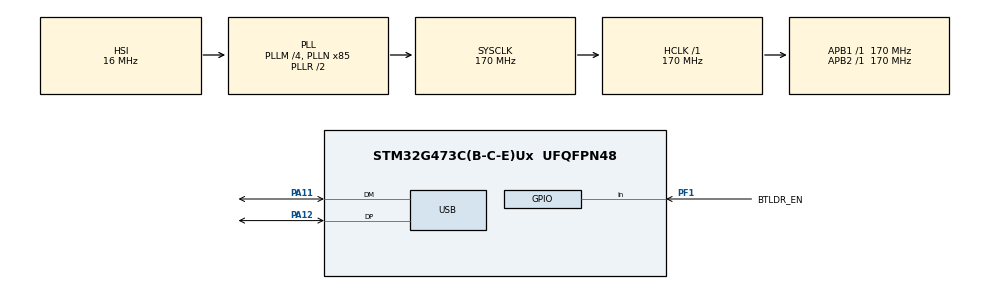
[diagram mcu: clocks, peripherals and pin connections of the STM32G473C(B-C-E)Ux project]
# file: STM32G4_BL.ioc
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Mcu.Family=STM32G4
Mcu.Name=STM32G473C(B-C-E)Ux
Mcu.Package=UFQFPN48
NVIC.PriorityGroup=NVIC_PRIORITYGROUP_4
NVIC.USB_LP_IRQn=true\:0\:0\:false\:false\:true\:true\:true
PA11.Mode=Device
PA11.Signal=USB_DM
PA12.Mode=Device
PA12.Signal=USB_DP
PA13.Mode=Trace_Asynchronous_SW
PA13.Signal=SYS_JTMS-SWDIO
PA14.Mode=Trace_Asynchronous_SW
PA14.Signal=SYS_JTCK-SWCLK
PB3.Mode=Trace_Asynchronous_SW
PB3.Signal=SYS_JTDO-SWO
PF1-OSC_OUT.GPIO_Label=BTLDR_EN
PF1-OSC_OUT.Signal=GPIO_Input
ProjectManager.HeapSize=0x200
ProjectManager.StackSize=0x400
ProjectManager.TargetToolchain=STM32CubeIDE
RCC.ADC12Freq_Value=170000000
RCC.ADC345Freq_Value=170000000
RCC.AHBFreq_Value=170000000
RCC.APB1Freq_Value=170000000
RCC.APB1TimFreq_Value=170000000
RCC.APB2Freq_Value=170000000
RCC.APB2TimFreq_Value=170000000
RCC.CK48CLockSelection=RCC_USBCLKSOURCE_HSI48
RCC.CortexFreq_Value=170000000
RCC.EXTERNAL_CLOCK_VALUE=12288000
RCC.HCLKFreq_Value=170000000
RCC.HSE_VALUE=8000000
RCC.HSI48_VALUE=48000000
RCC.HSI_VALUE=16000000
RCC.LSE_VALUE=32768
RCC.PLLM=RCC_PLLM_DIV4
RCC.PLLN=85
RCC.PLLQ=RCC_PLLQ_DIV6
RCC.SYSCLKFreq_VALUE=170000000
RCC.SYSCLKSource=RCC_SYSCLKSOURCE_PLLCLK
RCC.USBFreq_Value=48000000
RCC.VCOOutputFreq_Value=340000000
USB_DEVICE.CLASS_NAME_FS=MSC
USB_DEVICE.VirtualMode=Msc
USB_DEVICE.VirtualModeFS=Msc_FS
VP_SYS_VS_DBSignals.Mode=DisableDeadBatterySignals
VP_USB_DEVICE_VS_USB_DEVICE_MSC_FS.Mode=MSC_FS
board=custom

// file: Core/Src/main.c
/* USER CODE BEGIN Header */
/**
  ******************************************************************************
  * @file           : main.c
  * @brief          : Main program body
  ******************************************************************************
  * @attention
  *
  * <h2><center>&copy; Copyright (c) 2021 STMicroelectronics.
  * All rights reserved.</center></h2>
  *
  * This software component is licensed by ST under BSD 3-Clause license,
  * the "License"; You may not use this file except in compliance with the
  * License. You may obtain a copy of the License at:
  *                        opensource.org/licenses/BSD-3-Clause
  *
  * This bootloader project ported from https://github.com/sfyip/STM32F103_MSD_BOOTLOADER
  * by Brian Schmalz of SchmalzHaus LLC, August 2021.
  *
  ******************************************************************************
  */
/* USER CODE END Header */
#include "main.h"
#include "usb_device.h"
#include "gpio.h"

/* USER CODE BEGIN Includes */
#include <stdint.h>
#include <stdbool.h>
#include "btldr_config.h"
/* USER CODE END Includes */

void SystemClock_Config(void);

/* USER CODE BEGIN 0 */
bool is_appcode_exist()
{
  uint32_t *mem = (uint32_t*)APP_ADDR;

  if ((mem[0] == 0x00000000 || mem[0] == 0xFFFFFFFF) && \
      (mem[1] == 0x00000000 || mem[1] == 0xFFFFFFFF) && \
      (mem[2] == 0x00000000 || mem[2] == 0xFFFFFFFF) && \
      (mem[3] == 0x00000000 || mem[3] == 0xFFFFFFFF))
  {
    return false;
  }
  else
  {
    return true;
  }
}

void jmp_to_appcode()
{
  /* Function pointer to the address of the user application. */
  uint32_t jump_addr = *((__IO uint32_t*)(APP_ADDR+4u));
  __disable_irq();
  HAL_DeInit();
  /* Change the main stack pointer. */
  __set_MSP(*(__IO uint32_t*)APP_ADDR);
  SCB->VTOR = APP_ADDR;

  ((void (*) (void)) (jump_addr)) ();
}

/* USER CODE END 0 */

int main(void)
{

  /* MCU Configuration--------------------------------------------------------*/

  /* Reset of all peripherals, Initializes the Flash interface and the Systick. */
  HAL_Init();

  /* Configure the system clock */
  SystemClock_Config();

  /* Initialize all configured peripherals */
  MX_GPIO_Init();
  //MX_USB_Device_Init();
  /* USER CODE BEGIN 2 */
  /* The above call to MX_USB_Device_Init(); needs to be commented out. CubeMX will put it back, but we need
   * to conditionally init USB only if we need to actually run the bootloader.
   */
  Debug_SWOInit(0x00000001, 170000000, 2000000);

  /*
   * TODO: Make a 10 minute timeout for waiting for the user to copy a file over. If, after that time, there is no
   * file copied, then jump to the app (if it exists)
   *
   * TODO: Remove is_button_down() as trigger (done)
   *
   * TODO: Add 'double tap on reset button' as trigger (how?)
   *
   * TODO: Add code to erase second bank of flash (test with larger hex file)
   *
   * TODO: Add support for UF2 files (stretch goal)
   *
   * TODO: Add magic number method for APP to trigger bootloader
   *
   * TODO: Figure out how to make SWO work no matter if DEBUG/RELEASE or if debugger is connected or not
   *
   * TODO: Why is bootloader so big? Use ll libraries instead? How to shrink? (orig was 16KB)
   *
   */

  if(!is_appcode_exist() || (BL_FORCE_RAMLOC == BL_FORCE_RUN_MAGIC))
//  if(!is_appcode_exist())
  {
    uint32_t blink_time = HAL_GetTick();

    // Configure the Bootloader LED to be an output
    GPIO_InitTypeDef GPIO_InitStruct = {0};

    __HAL_RCC_GPIOA_CLK_ENABLE();
    HAL_GPIO_WritePin(BOOTLOADER_LED_PORT, BOOTLOADER_LED_PIN, GPIO_PIN_SET);
    GPIO_InitStruct.Pin = BOOTLOADER_LED_PIN;
    GPIO_InitStruct.Mode = GPIO_MODE_OUTPUT_PP;
    GPIO_InitStruct.Pull = GPIO_NOPULL;
    HAL_GPIO_Init(BOOTLOADER_LED_PORT, &GPIO_InitStruct);

    // Clear the BL_FORCE ram location so that we don't do this again
    BL_FORCE_RAMLOC = 0x00000000;

    printf("Entering bootloader\n");

    MX_USB_Device_Init();
    while(1)
    {
      if ((HAL_GetTick() - blink_time) > 1000)
      {
        if (HAL_GPIO_ReadPin(BOOTLOADER_LED_PORT, BOOTLOADER_LED_PIN) == GPIO_PIN_SET)
        {
          HAL_GPIO_WritePin(BOOTLOADER_LED_PORT, BOOTLOADER_LED_PIN, GPIO_PIN_RESET);
        }
        else
        {
          HAL_GPIO_WritePin(BOOTLOADER_LED_PORT, BOOTLOADER_LED_PIN, GPIO_PIN_SET);
        }
        blink_time = HAL_GetTick();
      }
    }
  }
  else
  {
    printf("Jumping to application.\n");
    jmp_to_appcode();
  }

  /* USER CODE END 2 */

  /* Infinite loop */
  while (1)
  {

  }
}

void SystemClock_Config(void)
{
  RCC_OscInitTypeDef RCC_OscInitStruct = {0};
  RCC_ClkInitTypeDef RCC_ClkInitStruct = {0};
  RCC_PeriphCLKInitTypeDef PeriphClkInit = {0};

  /** Configure the main internal regulator output voltage
  */
  HAL_PWREx_ControlVoltageScaling(PWR_REGULATOR_VOLTAGE_SCALE1_BOOST);
  /** Initializes the RCC Oscillators according to the specified parameters
  * in the RCC_OscInitTypeDef structure.
  */
  RCC_OscInitStruct.OscillatorType = RCC_OSCILLATORTYPE_HSI|RCC_OSCILLATORTYPE_HSI48;
  RCC_OscInitStruct.HSIState = RCC_HSI_ON;
  RCC_OscInitStruct.HSICalibrationValue = RCC_HSICALIBRATION_DEFAULT;
  RCC_OscInitStruct.HSI48State = RCC_HSI48_ON;
  RCC_OscInitStruct.PLL.PLLState = RCC_PLL_ON;
  RCC_OscInitStruct.PLL.PLLSource = RCC_PLLSOURCE_HSI;
  RCC_OscInitStruct.PLL.PLLM = RCC_PLLM_DIV4;
  RCC_OscInitStruct.PLL.PLLN = 85;
  RCC_OscInitStruct.PLL.PLLP = RCC_PLLP_DIV2;
  RCC_OscInitStruct.PLL.PLLQ = RCC_PLLQ_DIV6;
  RCC_OscInitStruct.PLL.PLLR = RCC_PLLR_DIV2;
  if (HAL_RCC_OscConfig(&RCC_OscInitStruct) != HAL_OK)
  {
    Error_Handler();
  }
  /** Initializes the CPU, AHB and APB buses clocks
  */
  RCC_ClkInitStruct.ClockType = RCC_CLOCKTYPE_HCLK|RCC_CLOCKTYPE_SYSCLK
                              |RCC_CLOCKTYPE_PCLK1|RCC_CLOCKTYPE_PCLK2;
  RCC_ClkInitStruct.SYSCLKSource = RCC_SYSCLKSOURCE_PLLCLK;
  RCC_ClkInitStruct.AHBCLKDivider = RCC_SYSCLK_DIV1;
  RCC_ClkInitStruct.APB1CLKDivider = RCC_HCLK_DIV1;
  RCC_ClkInitStruct.APB2CLKDivider = RCC_HCLK_DIV1;

  if (HAL_RCC_ClockConfig(&RCC_ClkInitStruct, FLASH_LATENCY_4) != HAL_OK)
  {
    Error_Handler();
  }
  /** Initializes the peripherals clocks
  */
  PeriphClkInit.PeriphClockSelection = RCC_PERIPHCLK_USB;
  PeriphClkInit.UsbClockSelection = RCC_USBCLKSOURCE_HSI48;
  if (HAL_RCCEx_PeriphCLKConfig(&PeriphClkInit) != HAL_OK)
  {
    Error_Handler();
  }
}

void Error_Handler(void)
{
  __disable_irq();
  while (1)
  {
  }
}

/************************ (C) COPYRIGHT STMicroelectronics *****END OF FILE****/
